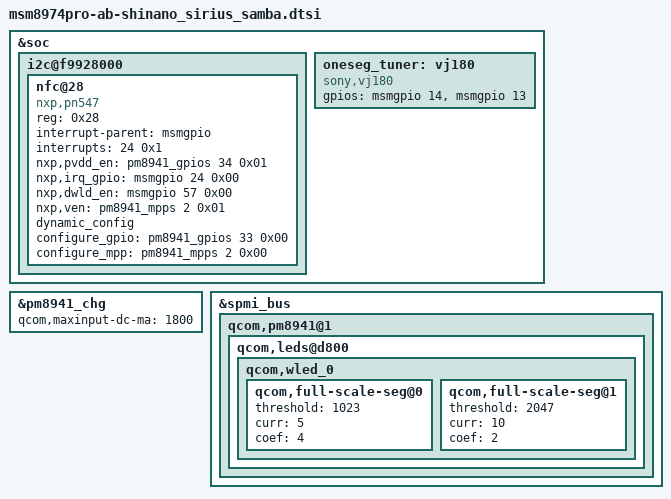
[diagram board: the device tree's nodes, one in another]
/* arch/arm/boot/dts/msm8974pro-ab-shinano_sirius_samba.dtsi
 *
 * Copyright (C) 2013 Sony Mobile Communications Inc.
 *
 * Author: Shougo Watanabe <Shougo.X.Watanabe@sonymobile.com>
 *
 * This program is free software; you can redistribute it and/or modify
 * it under the terms of the GNU General Public License version 2 and
 * only version 2 as published by the Free Software Foundation.
 *
 * This program is distributed in the hope that it will be useful,
 * but WITHOUT ANY WARRANTY; without even the implied warranty of
 * MERCHANTABILITY or FITNESS FOR A PARTICULAR PURPOSE.  See the
 * GNU General Public License for more details.
 */

&soc {
	/* I2C : BLSP6 */
	i2c@f9928000 {
		nfc@28 {
			compatible = "nxp,pn547";
			reg = <0x28>;
			interrupt-parent = <&msmgpio>;
			interrupts = <24 0x1>;
			nxp,pvdd_en = <&pm8941_gpios 34 0x01>;
			nxp,irq_gpio = <&msmgpio 24 0x00>;
			nxp,dwld_en = <&msmgpio 57 0x00>;
			nxp,ven = <&pm8941_mpps 2 0x01>;
			dynamic_config;
			configure_gpio = <&pm8941_gpios 33 0x00>;
			configure_mpp = <&pm8941_mpps 2 0x00>;
		};
	};

	oneseg_tuner: vj180 {
		compatible = "sony,vj180";
		gpios = <&msmgpio 14 0>, /* TUNER_POWER */
			<&msmgpio 13 0>; /* TUNER_RESET */
	};
};

&pm8941_chg {
	qcom,maxinput-dc-ma = <1800>;
};

&spmi_bus {
	qcom,pm8941@1 {
		qcom,leds@d800 {
			qcom,wled_0 {
				qcom,full-scale-seg@0 {
					threshold = <1023>;
					curr = <5>;
					coef = <4>;
				};
				qcom,full-scale-seg@1 {
					threshold = <2047>;
					curr = <10>;
					coef = <2>;
				};
			};
		};
	};
};
